# SN32F100 register map
Vendor: SONiX Technology Co., Ltd.; Series: SN32F100; File version: 1.3
CPU: CM0 r0p0, little endian, no MPU, no FPU, 2 interrupt priority bits
Registers are 32-bit, read-write, reset 0x0 unless marked. A register's access mark holds for its fields unless they carry their own. Offsets are from the block's base; [hi:lo] are bit positions; {n}, {i} and the like mark numbered series; 'fields as' and 'values as' point back to an identical list.

## SN_ADC — Codec ADC Control Registers
Base 0x40064000
0x540 SET1 reset 0x40 — Offset:0x540 ADC Setting 1 Register
  [7:0] LB_H — AGC Control Low bound setting : High byte
0x550 SET2 — Offset:0x550 ADC Setting 2 Register
  [7:0] LB_L — AGC Control Low bound setting : Low byte
0x560 SET3 reset 0x60 — Offset:0x560 ADC Setting 3 Register
  [7:0] HB_H — AGC Control High bound setting : High byte
0x570 SET4 — Offset:0x570 ADC Setting 4 Register
  [7:0] HB_L — AGC Control High bound setting : Low byte
0x580 SET5 reset 0x5 — Offset:0x580 ADC Setting 5 Register
  [3:0] NOR_POD — AGC Control Gain update period at normal mode
    {v}=1/Fs x 2^{v} (v=0..15)
0x590 SET6 reset 0xB — Offset:0x590 ADC Setting 6 Register
  [3:0] MUTE_POD — AGC Control Gain update period at mute mode
    {v}=1/Fs x 2^{v} (v=0..15)
0x5A0 SET7 reset 0x3 — Offset:0x5A0 ADC Setting 7 Register
  [7:0] SEARCH_TH_H — AGC Control Threshold for activating : High byte
0x5B0 SET8 — Offset:0x5B0 ADC Setting 8 Register
  [7:0] SEARCH_TH_L — AGC Control Threshold for activating : Low byte
0x5C0 SET9 reset 0x10 — Offset:0x5C0 ADC Setting 9 Register
  [7:0] MUTE_TH_H — AGC Control Threshold for inactivating : High byte
0x5D0 SET10 — Offset:0x5D0 ADC Setting 10 Register
  [7:0] MUTE_TH_L — AGC Control Threshold for inactivating : Low byte
0x5E0 SET11 reset 0x9 — Offset:0x5E0 ADC Setting 11 Register
  [3:0] MUTE_CAL_POD — AGC Control Period for inactivating
    {v}=256/Fs x 2^{v} (v=0..15)
0x5F0 SET12 reset 0x3 — Offset:0x5F0 ADC Setting 12 Register
  [3:0] SAT_TH — AGC Control Threshold for ADC saturation
0x600 SET13 reset 0xA — Offset:0x600 ADC Setting 13 Register
  [3:0] SAT_POD — AGC Control Period for ADC saturation
    {v}=1/Fs x 2^{v} (v=0..15)
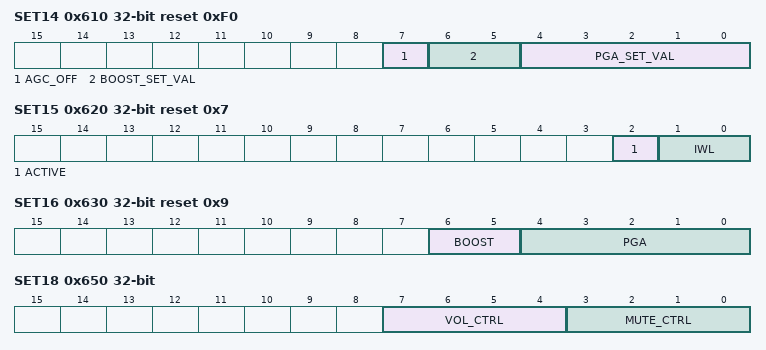
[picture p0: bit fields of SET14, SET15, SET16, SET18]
0x610 SET14 reset 0xF0 — Offset:0x610 ADC Setting 14 Register
  [7] AGC_OFF — AGC Control function
    0=Enable; 1=Disable
  [6:5] BOOST_SET_VAL — AGC Control Boost setting value at normal mode
    0=+0dB; 1=+12dB; 2=+20dB; 3=+30dB
  [4:0] PGA_SET_VAL — AGC Control PGA setting value at normal mode(1.5dB/step)
0x620 SET15 reset 0x7 — Offset:0x620 ADC Setting 15 Register
  [2] ACTIVE — Digital Audio Interface Control
    0=Disable; 1=Enable
  [1:0] IWL — World length of DAI
    0=16-bits; 1=18-bits; 2=20-bits; 3=24-bits
0x630 SET16 reset 0x9 — Offset:0x630 ADC Setting 16 Register
  [6:5] BOOST — Boost setting value
    0=+0dB; 1=+12dB; 2=+20dB; 3=+30dB
  [4:0] PGA — PGA setting value(1.5dB/step)
0x650 SET18 — Offset:0x650 ADC Setting 18 Register
  [7:4] VOL_CTRL — Digital volume attenuation control at normal mode
    0=0dB; 1=-3dB; 2=-6dB; 3=-9dB; 4=-12dB; 5=-15dB; 6=-18dB; 7=-21dB; 8=-24dB; 9=-27dB; 10=-30dB; 11=-36dB; 12=-42dB; 13=-48dB; 14=-54dB; 15=-78dB
  [3:0] MUTE_CTRL — Digital volume attenuation control at mute mode
    values as VOL_CTRL
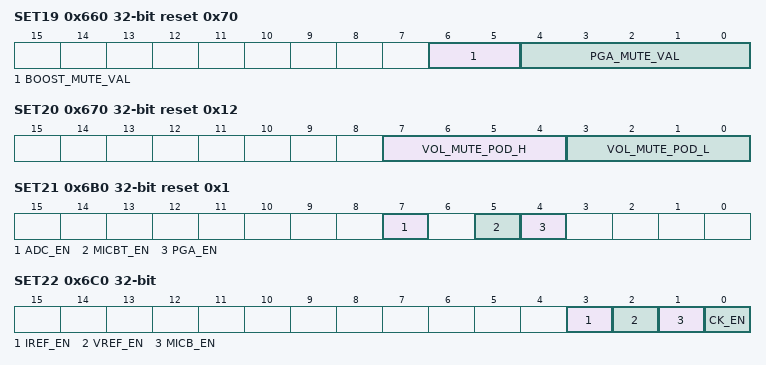
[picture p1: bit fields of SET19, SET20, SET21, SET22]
0x660 SET19 reset 0x70 — Offset:0x660 ADC Setting 19 Register
  [6:5] BOOST_MUTE_VAL — Boost setting value at mute mode
    0=+0dB; 1=+12dB; 2=+20dB; 3=+30dB
  [4:0] PGA_MUTE_VAL — PGA setting value at mute mode(1.5dB/step)
0x670 SET20 reset 0x12 — Offset:0x670 ADC Setting 20 Register
  [7:4] VOL_MUTE_POD_H — Period for Digital volume attenuation at normal mode
    {v}=1/Fs x 2^{v} (v=0..15)
  [3:0] VOL_MUTE_POD_L — Period for Digital volume attenuation at mute mode
    {v}=1/Fs x 2^{v} (v=0..15)
0x6B0 SET21 reset 0x1 — Offset:0x6B0 ADC Setting 21 Register
  [all] fields
    0=Disable; 1=Enable
  [7] ADC_EN — ADC power-on enable
  [5] MICBT_EN — MICBOOST power-on enable
  [4] PGA_EN — PGA power-on enable
0x6C0 SET22 — Offset:0x6C0 ADC Setting 22 Register
  [all] fields
    0=Disable; 1=Enable
  [3] IREF_EN — IREF circuit enable
  [2] VREF_EN — VREF circuit enable
  [1] MICB_EN — Microphone bias enable
  [0] CK_EN — CKGEN enable
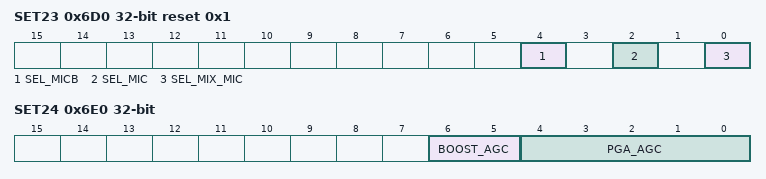
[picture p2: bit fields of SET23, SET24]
0x6D0 SET23 reset 0x1 — Offset:0x6D0 ADC Setting 23 Register
  [4] SEL_MICB — Microphone Bias Output select
    0=0.8*VA; 1=0.9*VA
  [2] SEL_MIC — P1.7/MIC_P and P1.8/MIC_N function selection
    0=General purpose IO; 1=Microphone Differential input
  [0] SEL_MIX_MIC — Microphone input path to mixer enable
    0=Disable; 1=Enable
0x6E0 SET24 ro — Offset:0x6E0 ADC Setting 24 Register
  [6:5] BOOST_AGC — Boost setting value when AGC is on
  [4:0] PGA_AGC — PGA setting value when AGC is on
